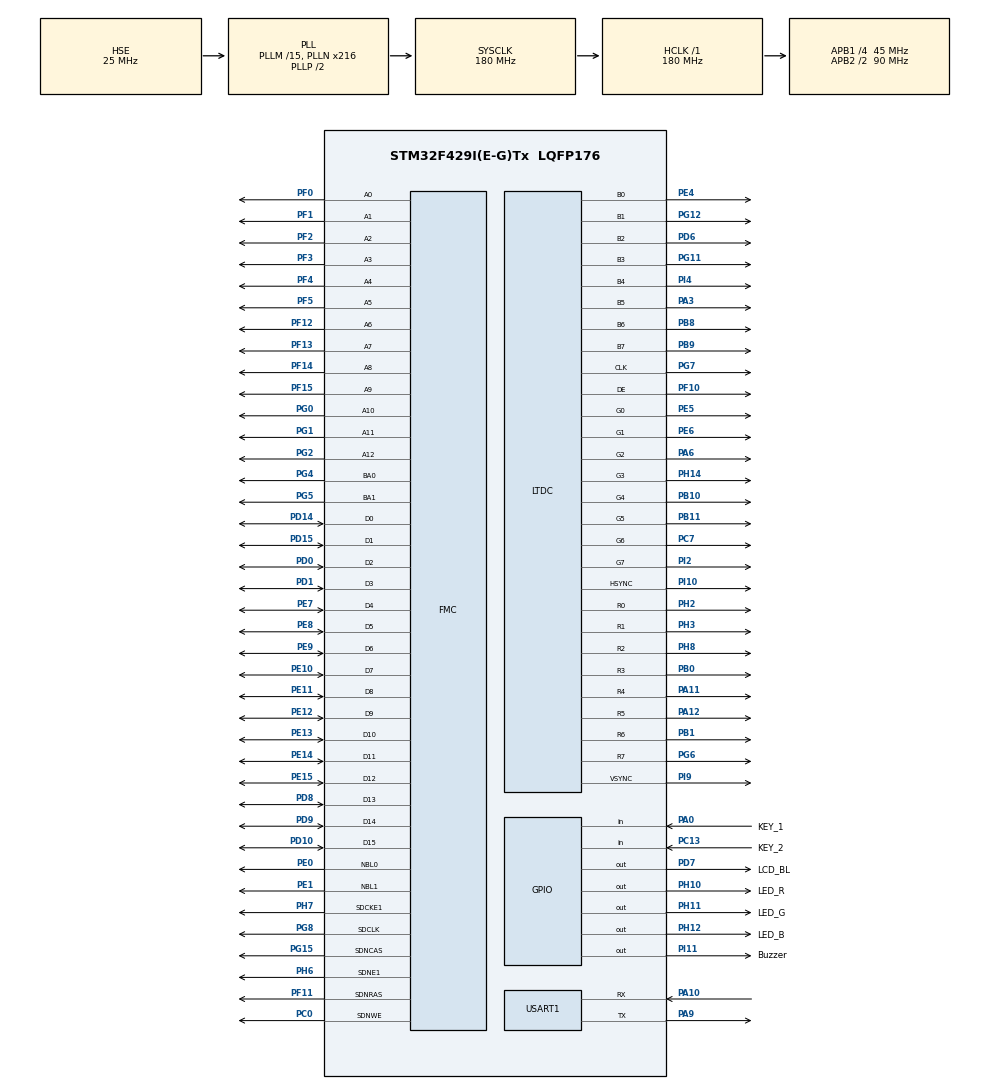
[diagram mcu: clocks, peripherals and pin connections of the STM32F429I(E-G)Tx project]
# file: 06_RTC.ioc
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DMA2D.ColorMode=DMA2D_OUTPUT_RGB565
DMA2D.Mode=DMA2D_R2M
FMC.CASLatency2=FMC_SDRAM_CAS_LATENCY_3
FMC.ColumnBitsNumber2=FMC_SDRAM_COLUMN_BITS_NUM_9
FMC.ExitSelfRefreshDelay2=7
FMC.LoadToActiveDelay2=2
FMC.RCDDelay2=2
FMC.RPDelay1=2
FMC.RPDelay2=2
FMC.ReadBurst1=FMC_SDRAM_RBURST_ENABLE
FMC.ReadBurst2=FMC_SDRAM_RBURST_ENABLE
FMC.ReadPipeDelay2=FMC_SDRAM_RPIPE_DELAY_0
FMC.RowCycleDelay1=6
FMC.RowCycleDelay2=6
FMC.SDClockPeriod1=FMC_SDRAM_CLOCK_PERIOD_2
FMC.SDClockPeriod2=FMC_SDRAM_CLOCK_PERIOD_2
FMC.SelfRefreshTime2=4
FMC.WriteRecoveryTime2=2
LTDC.ActiveH=480
LTDC.ActiveW=800
LTDC.Alpha0_L0=0
LTDC.Alpha_L0=0xff
LTDC.Alpha_L1=0xff
LTDC.BlendingFactor1_L0=LTDC_BLENDING_FACTOR1_PAxCA
LTDC.BlendingFactor1_L1=LTDC_BLENDING_FACTOR1_PAxCA
LTDC.BlendingFactor2_L0=LTDC_BLENDING_FACTOR2_PAxCA
LTDC.BlendingFactor2_L1=LTDC_BLENDING_FACTOR2_PAxCA
LTDC.DEPolarity=LTDC_DEPOLARITY_AL
LTDC.FBStartAdress_L0=0xD0000000
LTDC.FBStartAdress_L1=0xD0200000
LTDC.HBP=46
LTDC.HFP=22
LTDC.HSync=1
LTDC.ImageHeight_L0=480
LTDC.ImageHeight_L1=480
LTDC.ImageWidth_L0=800
LTDC.ImageWidth_L1=800
LTDC.Layers=1
LTDC.PCPolarity=LTDC_PCPOLARITY_IPC
LTDC.PixelFormat_L0=LTDC_PIXEL_FORMAT_RGB565
LTDC.PixelFormat_L1=LTDC_PIXEL_FORMAT_RGB565
LTDC.Red_L0=0
LTDC.Red_L1=0
LTDC.VBP=23
LTDC.VFP=13
LTDC.VSync=3
LTDC.WindowX1_L0=799
LTDC.WindowX1_L1=799
LTDC.WindowY1_L0=479
LTDC.WindowY1_L1=479
Mcu.Family=STM32F4
Mcu.Name=STM32F429I(E-G)Tx
Mcu.Package=LQFP176
NVIC.PriorityGroup=NVIC_PRIORITYGROUP_4
PA0/WKUP.GPIO_Label=KEY_1
PA0/WKUP.Signal=GPIO_Input
PA10.Mode=Asynchronous
PA10.Signal=USART1_RX
PA11.Mode=RGB888
PA11.Signal=LTDC_R4
PA12.Mode=RGB888
PA12.Signal=LTDC_R5
PA13.Mode=Serial_Wire
PA13.Signal=SYS_JTMS-SWDIO
PA14.Mode=Serial_Wire
PA14.Signal=SYS_JTCK-SWCLK
PA3.Mode=RGB888
PA3.Signal=LTDC_B5
PA6.Mode=RGB888
PA6.Signal=LTDC_G2
PA9.Mode=Asynchronous
PA9.Signal=USART1_TX
PB0.Mode=RGB888
PB0.Signal=LTDC_R3
PB1.Mode=RGB888
PB1.Signal=LTDC_R6
PB10.Mode=RGB888
PB10.Signal=LTDC_G4
PB11.Mode=RGB888
PB11.Signal=LTDC_G5
PB8.Mode=RGB888
PB8.Signal=LTDC_B6
PB9.Mode=RGB888
PB9.Signal=LTDC_B7
PC0.Signal=FMC_SDNWE
PC13.GPIO_Label=KEY_2
PC13.Signal=GPIO_Input
PC14/OSC32_IN.Mode=LSE-External-Oscillator
PC14/OSC32_IN.Signal=RCC_OSC32_IN
PC15/OSC32_OUT.Mode=LSE-External-Oscillator
PC15/OSC32_OUT.Signal=RCC_OSC32_OUT
PC7.Mode=RGB888
PC7.Signal=LTDC_G6
PD0.Signal=FMC_D2_DA2
PD1.Signal=FMC_D3_DA3
PD10.Signal=FMC_D15_DA15
PD14.Signal=FMC_D0_DA0
PD15.Signal=FMC_D1_DA1
PD6.Mode=RGB888
PD6.Signal=LTDC_B2
PD7.GPIO_Label=LCD_BL
PD7.PinState=GPIO_PIN_SET
PD7.Signal=GPIO_Output
PD8.Signal=FMC_D13_DA13
PD9.Signal=FMC_D14_DA14
PE0.Signal=FMC_NBL0
PE1.Signal=FMC_NBL1
PE10.Signal=FMC_D7_DA7
PE11.Signal=FMC_D8_DA8
PE12.Signal=FMC_D9_DA9
PE13.Signal=FMC_D10_DA10
PE14.Signal=FMC_D11_DA11
PE15.Signal=FMC_D12_DA12
PE4.Mode=RGB888
PE4.Signal=LTDC_B0
PE5.Mode=RGB888
PE5.Signal=LTDC_G0
PE6.Mode=RGB888
PE6.Signal=LTDC_G1
PE7.Signal=FMC_D4_DA4
PE8.Signal=FMC_D5_DA5
PE9.Signal=FMC_D6_DA6
PF0.Signal=FMC_A0
PF1.Signal=FMC_A1
PF10.Mode=RGB888
PF10.Signal=LTDC_DE
PF11.Signal=FMC_SDNRAS
PF12.Signal=FMC_A6
PF13.Signal=FMC_A7
PF14.Signal=FMC_A8
PF15.Signal=FMC_A9
PF2.Signal=FMC_A2
PF3.Signal=FMC_A3
PF4.Signal=FMC_A4
PF5.Signal=FMC_A5
PG0.Signal=FMC_A10
PG1.Signal=FMC_A11
PG11.Mode=RGB888
PG11.Signal=LTDC_B3
PG12.Mode=RGB888
PG12.Signal=LTDC_B1
PG15.Signal=FMC_SDNCAS
PG2.Signal=FMC_A12
PG4.Signal=FMC_A14_BA0
PG5.Signal=FMC_A15_BA1
PG6.Mode=RGB888
PG6.Signal=LTDC_R7
PG7.Mode=RGB888
PG7.Signal=LTDC_CLK
PG8.Signal=FMC_SDCLK
PH0/OSC_IN.Mode=HSE-External-Oscillator
PH0/OSC_IN.Signal=RCC_OSC_IN
PH1/OSC_OUT.Mode=HSE-External-Oscillator
PH1/OSC_OUT.Signal=RCC_OSC_OUT
PH10.GPIO_Label=LED_R
PH10.PinState=GPIO_PIN_SET
PH10.Signal=GPIO_Output
PH11.GPIO_Label=LED_G
PH11.PinState=GPIO_PIN_SET
PH11.Signal=GPIO_Output
PH12.GPIO_Label=LED_B
PH12.PinState=GPIO_PIN_SET
PH12.Signal=GPIO_Output
PH14.Mode=RGB888
PH14.Signal=LTDC_G3
PH2.Mode=RGB888
PH2.Signal=LTDC_R0
PH3.Mode=RGB888
PH3.Signal=LTDC_R1
PH6.Mode=SdramChipSelect2_2
PH6.Signal=FMC_SDNE1
PH7.Mode=SdramChipSelect2_2
PH7.Signal=FMC_SDCKE1
PH8.Mode=RGB888
PH8.Signal=LTDC_R2
PI10.Mode=RGB888
PI10.Signal=LTDC_HSYNC
PI11.GPIO_Label=Buzzer
PI11.PinState=GPIO_PIN_RESET
PI11.Signal=GPIO_Output
PI2.Mode=RGB888
PI2.Signal=LTDC_G7
PI4.Mode=RGB888
PI4.Signal=LTDC_B4
PI9.Mode=RGB888
PI9.Signal=LTDC_VSYNC
ProjectManager.HeapSize=0x200
ProjectManager.StackSize=0x400
ProjectManager.TargetToolchain=CMake
RCC.48MHZClocksFreq_Value=90000000
RCC.AHBFreq_Value=180000000
RCC.APB1CLKDivider=RCC_HCLK_DIV4
RCC.APB1Freq_Value=45000000
RCC.APB1TimFreq_Value=90000000
RCC.APB2CLKDivider=RCC_HCLK_DIV2
RCC.APB2Freq_Value=90000000
RCC.APB2TimFreq_Value=180000000
RCC.CortexFreq_Value=180000000
RCC.FLatency=FLASH_LATENCY_5
RCC.HCLKFreq_Value=180000000
RCC.HSE_VALUE=25000000
RCC.HSI_VALUE=16000000
RCC.PLLM=15
RCC.PLLN=216
RCC.PLLSAIDivR=RCC_PLLSAIDIVR_4
RCC.PLLSAIN=90
RCC.PLLSourceVirtual=RCC_PLLSOURCE_HSE
RCC.PWREXT_OverDrive=PWREXT_OverDrive_ACTIVATED
RCC.PWR_Regulator_Voltage_Scale=PWR_REGULATOR_VOLTAGE_SCALE1
RCC.RCC_RTC_Clock_Source=RCC_RTCCLKSOURCE_LSE
RCC.RCC_RTC_Clock_SourceVirtual=RCC_RTCCLKSOURCE_LSE
RCC.SYSCLKFreq_VALUE=180000000
RCC.SYSCLKSource=RCC_SYSCLKSOURCE_PLLCLK
RCC.VCOOutputFreq_Value=360000000
SH.FMC_A0.0=FMC_A0,13b-sda2
SH.FMC_A1.0=FMC_A1,13b-sda2
SH.FMC_A10.0=FMC_A10,13b-sda2
SH.FMC_A11.0=FMC_A11,13b-sda2
SH.FMC_A12.0=FMC_A12,13b-sda2
SH.FMC_A14_BA0.0=FMC_BA0,FourSdramBanks2
SH.FMC_A15_BA1.0=FMC_BA1,FourSdramBanks2
SH.FMC_A2.0=FMC_A2,13b-sda2
SH.FMC_A3.0=FMC_A3,13b-sda2
SH.FMC_A4.0=FMC_A4,13b-sda2
SH.FMC_A5.0=FMC_A5,13b-sda2
SH.FMC_A6.0=FMC_A6,13b-sda2
SH.FMC_A7.0=FMC_A7,13b-sda2
SH.FMC_A8.0=FMC_A8,13b-sda2
SH.FMC_A9.0=FMC_A9,13b-sda2
SH.FMC_D0_DA0.0=FMC_D0,sd-16b-d2
SH.FMC_D10_DA10.0=FMC_D10,sd-16b-d2
SH.FMC_D11_DA11.0=FMC_D11,sd-16b-d2
SH.FMC_D12_DA12.0=FMC_D12,sd-16b-d2
SH.FMC_D13_DA13.0=FMC_D13,sd-16b-d2
SH.FMC_D14_DA14.0=FMC_D14,sd-16b-d2
SH.FMC_D15_DA15.0=FMC_D15,sd-16b-d2
SH.FMC_D1_DA1.0=FMC_D1,sd-16b-d2
SH.FMC_D2_DA2.0=FMC_D2,sd-16b-d2
SH.FMC_D3_DA3.0=FMC_D3,sd-16b-d2
SH.FMC_D4_DA4.0=FMC_D4,sd-16b-d2
SH.FMC_D5_DA5.0=FMC_D5,sd-16b-d2
SH.FMC_D6_DA6.0=FMC_D6,sd-16b-d2
SH.FMC_D7_DA7.0=FMC_D7,sd-16b-d2
SH.FMC_D8_DA8.0=FMC_D8,sd-16b-d2
SH.FMC_D9_DA9.0=FMC_D9,sd-16b-d2
SH.FMC_NBL0.0=FMC_NBL0,Sd2ByteEnable2
SH.FMC_NBL1.0=FMC_NBL1,Sd2ByteEnable2
SH.FMC_SDCLK.0=FMC_SDCLK,13b-sda2
SH.FMC_SDNCAS.0=FMC_SDNCAS,13b-sda2
SH.FMC_SDNRAS.0=FMC_SDNRAS,13b-sda2
SH.FMC_SDNWE.0=FMC_SDNWE,13b-sda2
USART1.VirtualMode=VM_ASYNC
VP_DMA2D_VS_DMA2D.Mode=DMA2D_Activate
VP_RTC_VS_RTC_Activate.Mode=RTC_Enabled
VP_RTC_VS_RTC_Calendar.Mode=RTC_Calendar
board=custom

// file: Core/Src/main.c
/* USER CODE BEGIN Header */
/**
 ******************************************************************************
 * @file           : main.c
 * @brief          : Main program body
 ******************************************************************************
 * @attention
 *
 * Copyright (c) 2026 STMicroelectronics.
 * All rights reserved.
 *
 * This software is licensed under terms that can be found in the LICENSE file
 * in the root directory of this software component.
 * If no LICENSE file comes with this software, it is provided AS-IS.
 *
 ******************************************************************************
 */
/* USER CODE END Header */
#include "main.h"
#include "dma2d.h"
#include "ltdc.h"
#include "rtc.h"
#include "usart.h"
#include "gpio.h"
#include "fmc.h"

/* USER CODE BEGIN Includes */
#include "bsp_config.h"
#include "bsp_lcd.h"
#include <stdint.h>
#include <stdio.h>
#include <string.h>

/* USER CODE END Includes */

void SystemClock_Config(void);

int main(void)
{

  /* MCU Configuration--------------------------------------------------------*/

  /* Reset of all peripherals, Initializes the Flash interface and the Systick. */
  HAL_Init();

  /* Configure the system clock */
  SystemClock_Config();

  /* Initialize all configured peripherals */
  MX_GPIO_Init();
  MX_USART1_UART_Init();
  MX_FMC_Init();
  MX_LTDC_Init();
  MX_DMA2D_Init();
  MX_RTC_Init();
  /* USER CODE BEGIN 2 */
  SDRAM_Initialization_Sequence(&hsdram2);

#if 0 // Test LCD Driver
  BSP_LCD_Test();
#endif

  // Test BSP_LCD_Printf
  BSP_LCD_SetOrientation(270);
  BSP_LCD_SetPixelFormat(LCD_PIXEL_FORMAT_RGB565);
  BSP_LCD_SetActiveLayer(LCD_LAYER_FG);
  BSP_LCD_FillForeground(COLOR_BLACK);
  BSP_LCD_SetCursor(0, 0);
  BSP_LCD_SetBgColor(COLOR_BLACK);
  BSP_LCD_SetColor(COLOR_RED);
  BSP_LCD_SetFont(&Font16);

  BSP_LCD_Printf("LCD Printf Test\n");
  printf("hello world\n");
  printf("this is a test string.\n");
  RTC_TimeTypeDef RTC_Time = {0};
  RTC_DateTypeDef RTC_Date = {0}; // 必须定义日期结构体

  /* USER CODE END 2 */

  /* Infinite loop */
  /* USER CODE BEGIN WHILE */
  while (1)
  {

    // 读取RTC时间
    HAL_RTC_GetTime(&hrtc, &RTC_Time, RTC_FORMAT_BIN);
    HAL_RTC_GetDate(&hrtc, &RTC_Date, RTC_FORMAT_BIN);
    // 显示RTC时间

    BSP_LCD_SetColor(COLOR_RED);
    BSP_LCD_SetFont(&Font24);
    BSP_LCD_Printf("Time: %02d:%02d:%02d\n", RTC_Time.Hours, RTC_Time.Minutes, RTC_Time.Seconds);

    BSP_LCD_SetColor(COLOR_GREEN);
    BSP_LCD_Printf("Date: 20%02d-%02d-%02d\n", RTC_Date.Year, RTC_Date.Month, RTC_Date.Date);
    HAL_Delay(1000);
  }

    /* USER CODE END WHILE */

}

void SystemClock_Config(void)
{
  RCC_OscInitTypeDef RCC_OscInitStruct = {0};
  RCC_ClkInitTypeDef RCC_ClkInitStruct = {0};

  /** Configure the main internal regulator output voltage
  */
  __HAL_RCC_PWR_CLK_ENABLE();
  __HAL_PWR_VOLTAGESCALING_CONFIG(PWR_REGULATOR_VOLTAGE_SCALE1);

  /** Initializes the RCC Oscillators according to the specified parameters
  * in the RCC_OscInitTypeDef structure.
  */
  RCC_OscInitStruct.OscillatorType = RCC_OSCILLATORTYPE_HSE|RCC_OSCILLATORTYPE_LSE;
  RCC_OscInitStruct.HSEState = RCC_HSE_ON;
  RCC_OscInitStruct.LSEState = RCC_LSE_ON;
  RCC_OscInitStruct.PLL.PLLState = RCC_PLL_ON;
  RCC_OscInitStruct.PLL.PLLSource = RCC_PLLSOURCE_HSE;
  RCC_OscInitStruct.PLL.PLLM = 15;
  RCC_OscInitStruct.PLL.PLLN = 216;
  RCC_OscInitStruct.PLL.PLLP = RCC_PLLP_DIV2;
  RCC_OscInitStruct.PLL.PLLQ = 4;
  if (HAL_RCC_OscConfig(&RCC_OscInitStruct) != HAL_OK)
  {
    Error_Handler();
  }

  /** Activate the Over-Drive mode
  */
  if (HAL_PWREx_EnableOverDrive() != HAL_OK)
  {
    Error_Handler();
  }

  /** Initializes the CPU, AHB and APB buses clocks
  */
  RCC_ClkInitStruct.ClockType = RCC_CLOCKTYPE_HCLK|RCC_CLOCKTYPE_SYSCLK
                              |RCC_CLOCKTYPE_PCLK1|RCC_CLOCKTYPE_PCLK2;
  RCC_ClkInitStruct.SYSCLKSource = RCC_SYSCLKSOURCE_PLLCLK;
  RCC_ClkInitStruct.AHBCLKDivider = RCC_SYSCLK_DIV1;
  RCC_ClkInitStruct.APB1CLKDivider = RCC_HCLK_DIV4;
  RCC_ClkInitStruct.APB2CLKDivider = RCC_HCLK_DIV2;

  if (HAL_RCC_ClockConfig(&RCC_ClkInitStruct, FLASH_LATENCY_5) != HAL_OK)
  {
    Error_Handler();
  }
}

void Error_Handler(void)
{
  __disable_irq();
}
